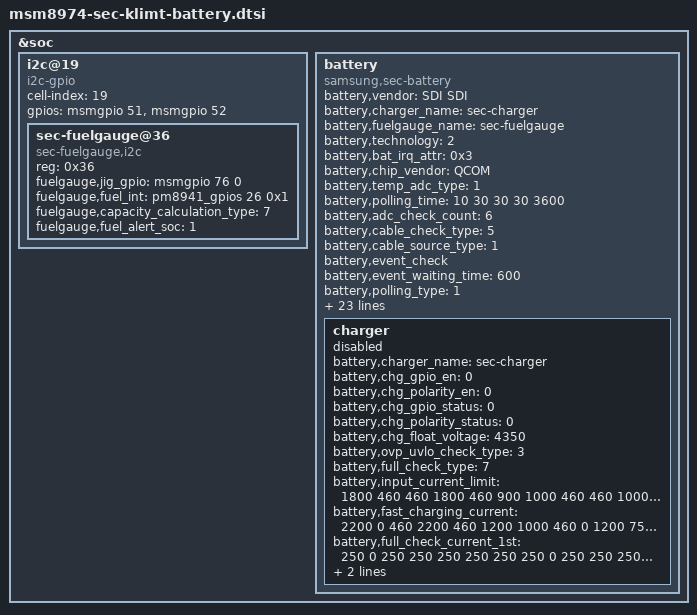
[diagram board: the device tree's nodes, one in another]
/* Copyright (c) 2012, The Linux Foundation. All rights reserved.
 *
 * This program is free software; you can redistribute it and/or modify
 * it under the terms of the GNU General Public License version 2 and
 * only version 2 as published by the Free Software Foundation.
 *
 * This program is distributed in the hope that it will be useful,
 * but WITHOUT ANY WARRANTY; without even the implied warranty of
 * MERCHANTABILITY or FITNESS FOR A PARTICULAR PURPOSE.  See the
 * GNU General Public License for more details.
 */

&soc {

	i2c@19 {
		cell-index = <19>;
		compatible = "i2c-gpio";
		gpios = <&msmgpio 51 0 /* sda */
			&msmgpio 52 0 /* scl */
			>;
		sec-fuelgauge@36 {
			compatible = "sec-fuelgauge,i2c";
			reg = <0x36>;
			fuelgauge,jig_gpio = <&msmgpio 76 0>;
			fuelgauge,fuel_int = <&pm8941_gpios 26 0x1>;
			fuelgauge,capacity_calculation_type = <7>;
			fuelgauge,fuel_alert_soc = <1>;
		};
	};

	battery {
		status = "okay";
		compatible = "samsung,sec-battery";
		battery,vendor = "SDI SDI";
		battery,charger_name = "sec-charger";
		battery,fuelgauge_name = "sec-fuelgauge";
		battery,technology = <2>; /* POWER_SUPPLY_TECHNOLOGY_LION */
		battery,bat_irq_attr = <0x3>;

		battery,chip_vendor = "QCOM";
		battery,temp_adc_type = <1>; /* SEC_BATTERY_ADC_TYPE_AP */

		battery,polling_time = <10 30 30 30 3600>;

		battery,adc_check_count = <6>;

		battery,cable_check_type = <5>; /* SEC_BATTERY_CABLE_CHECK_NOUSBCHARGE | SEC_BATTERY_CABLE_CHECK_PSY */
		battery,cable_source_type = <1>; /* SEC_BATTERY_CABLE_SOURCE_EXTERNAL */
		battery,event_check;
		battery,event_waiting_time = <600>;
		battery,polling_type = <1>; /* SEC_BATTERY_MONITOR_ALARM */
		battery,monitor_initial_count = <3>;

		battery,battery_check_type = <4>; /* SEC_BATTERY_CHECK_FUELGAUGE */
		battery,check_count = <0>;
		battery,check_adc_max = <1440>;
		battery,check_adc_min = <0>;

		battery,ovp_uvlo_check_type = <3>; /* SEC_BATTERY_OVP_UVLO_CHGPOLLING */

		battery,thermal_source = <0>; /* SEC_BATTERY_THERMAL_SOURCE_FG */

		battery,temp_check_type = <2>; /* _BATTERY_TEMP_CHECK_TEMP */
		battery,temp_check_count = <1>;
		battery,full_check_type = <7>; /* SEC_BATTERY_FULLCHARGED_CHGPSY */
		battery,full_check_type_2nd = <0>; /* SEC_BATTERY_FULLCHARGED_NONE */
		battery,full_check_count = <1>;
		battery,chg_gpio_full_check = <0>;
		battery,chg_polarity_full_check = <1>;

		/* SEC_BATTERY_FULL_CONDITION_SOC |
		   SEC_BATTERY_FULL_CONDITION_NOTIMEFULL |
		   SEC_BATTERY_FULL_CONDITION_VCELL */
		battery,full_condition_type = <13>;
		battery,full_condition_soc = <93>;
		battery,full_condition_vcell = <4250>;

		battery,recharge_check_count = <1>;
		battery,recharge_condition_type = <4>; /* SEC_BATTERY_RECHARGE_CONDITION_VCELL */
		battery,recharge_condition_vcell = <4300>;

		battery,charging_total_time = <36000>;
		battery,recharging_total_time = <5400>;
		battery,charging_reset_time = <0>;

		charger{
			status = "disable";
			/* Charger */
			battery,charger_name = "sec-charger";
			battery,chg_gpio_en = <0>;
			battery,chg_polarity_en = <0>;
			battery,chg_gpio_status = <0>;
			battery,chg_polarity_status = <0>;
			battery,chg_float_voltage = <4350>;
			battery,ovp_uvlo_check_type = <3>; /* SEC_BATTERY_OVP_UVLO_CHGPOLLING */
			battery,full_check_type = <7>; /* SEC_BATTERY_FULLCHARGED_CHGPSY */

			battery,input_current_limit = <1800 460 460 1800 460 900 1000 460 460 1000 650 1800 1800 460 1300 300 700 1300 300 1000 1800 460 460 0 1800 80 460 460 460 1400 460>;
			battery,fast_charging_current = <2200 0 460 2200 460 1200 1000 460 0 1200 750 2200 2200 0 1300 300 700 1300 300 1000 2200 0 0 0 1800 80 0 0 0 1400 460>;
			battery,full_check_current_1st = <250 0 250 250 250 250 250 250 0 250 250 250 250 0 250 250 250 250 250 250 250 0 0 0 250 0 0 0 0 250 250>;
			battery,full_check_current_2nd = <250 0 250 250 250 250 250 250 0 250 250 250 250 0 250 250 250 250 250 250 250 0 0 0 250 250 0 0 0 250 250>;
		};
	};
};
